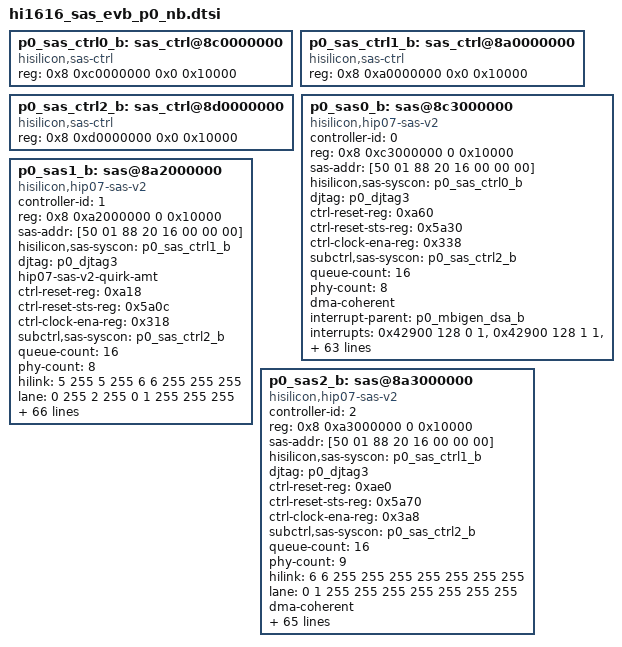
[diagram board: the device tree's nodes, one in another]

		p0_sas_ctrl0_b: sas_ctrl@8c0000000 {
			compatible = "hisilicon,sas-ctrl", "syscon";
			reg = <0x8 0xc0000000 0x0 0x10000>;
		};

		p0_sas_ctrl1_b: sas_ctrl@8a0000000 {
			compatible = "hisilicon,sas-ctrl", "syscon";
			reg = <0x8 0xa0000000 0x0 0x10000>;
		};

		p0_sas_ctrl2_b: sas_ctrl@8d0000000 {
			compatible = "hisilicon,sas-ctrl", "syscon";
			reg = <0x8 0xd0000000 0x0 0x10000>;
		};

		p0_sas0_b: sas@8c3000000 {
			compatible = "hisilicon,hip07-sas-v2";
			controller-id = <0>;
			reg = <0x8 0xc3000000 0 0x10000>;
			sas-addr = [50 01 88 20 16 00 00 00];
			hisilicon,sas-syscon = <&p0_sas_ctrl0_b>;
			djtag = <&p0_djtag3>;
			ctrl-reset-reg = <0xa60>;
			ctrl-reset-sts-reg = <0x5a30>;
			ctrl-clock-ena-reg = <0x338>;
			subctrl,sas-syscon = <&p0_sas_ctrl2_b>;
			queue-count = <16>;
			phy-count = <8>;
			dma-coherent;
			interrupt-parent = <&p0_mbigen_dsa_b>;
			interrupts = <0x42900 128 0 1>,
			<0x42900 128 1 1>,
			<0x42900 128 2 1>,
			<0x42900 128 3 1>,
			<0x42900 128 4 1>,
			<0x42900 128 5 1>,
			<0x42900 128 6 1>,
			<0x42900 128 7 1>,
			<0x42900 128 8 1>,
			<0x42900 128 9 1>,
			<0x42900 128 10 1>,
			<0x42900 128 11 1>,
			<0x42900 128 12 1>,
			<0x42900 128 13 1>,
			<0x42900 128 14 1>,
			<0x42900 128 15 1>,
			<0x42900 128 16 1>,
			<0x42900 128 17 1>,
			<0x42900 128 18 1>,
			<0x42900 128 19 1>,
			<0x42900 128 20 1>,
			<0x42900 128 21 1>,
			<0x42900 128 22 1>,
			<0x42900 128 23 1>,
			<0x42900 128 24 1>,
			<0x42900 128 25 1>,
			<0x42900 128 26 1>,
			<0x42900 128 27 1>,
			<0x42900 128 28 1>,
			<0x42900 128 29 1>,
			<0x42900 128 30 1>,
			<0x42900 128 31 1>,
			<0x42900 128 32 1>,
			<0x42900 128 33 1>,
			<0x42900 128 34 1>,
			<0x42900 128 35 1>,
			<0x42900 128 36 1>,
			<0x42900 128 37 1>,
			<0x42900 128 38 1>,
			<0x42900 128 39 1>,
			<0x42900 128 40 1>,
			<0x42900 128 41 1>,
			<0x42900 128 42 1>,
			<0x42900 128 43 1>,
			<0x42900 128 44 1>,
			<0x42900 128 45 1>,
			<0x42900 128 46 1>,
			<0x42900 128 47 1>,
			<0x42900 128 48 1>,
			<0x42900 128 49 1>,
			<0x42900 128 50 1>,
			<0x42900 128 51 1>,
			<0x42900 128 52 1>,
			<0x42900 128 53 1>,
			<0x42900 128 54 1>,
			<0x42900 128 55 1>,
			<0x42900 128 56 1>,
			<0x42900 128 57 1>,
			<0x42900 128 58 1>,
			<0x42900 128 59 1>,
			<0x42900 128 60 1>,
			<0x42900 128 61 1>,
			<0x42900 128 62 1>,
			<0x42900 128 63 1>,
			<0x42900 128 64 1>,
			<0x42900 128 65 1>,
			<0x42900 128 66 1>,
			<0x42900 128 67 1>,
			<0x42900 128 68 1>,
			<0x42900 128 69 1>,
			<0x42900 128 70 1>,
			<0x42900 128 71 1>,
			<0x42900 128 72 1>,
			<0x42900 128 73 1>,
			<0x42900 128 74 1>,
			<0x42900 128 75 1>,
			<0x42900 128 76 1>,
			<0x42900 128 77 1>,
			<0x42900 128 78 1>,
			<0x42900 128 79 1>,
			<0x42900 128 80 1>,
			<0x42900 128 81 1>,
			<0x42900 128 82 1>,
			<0x42900 128 83 1>,
			<0x42900 128 84 1>,
			<0x42900 128 85 1>,
			<0x42900 128 86 1>,
			<0x42900 128 87 1>,
			<0x42900 128 88 1>,
			<0x42900 128 89 1>,
			<0x42900 128 90 1>,
			<0x42900 128 91 1>,
			<0x42900 128 92 1>,
			<0x42900 128 93 1>,
			<0x42900 128 94 1>,
			<0x42900 128 95 1>,
			<0x42900 128 25 5>,
			<0x42900 128 26 5>,
			<0x42900 128 27 5>,
			<0x42900 128 28 5>,
			<0x42900 128 29 5>,
			<0x42900 128 30 5>,
			<0x42900 128 31 5>,
			<0x42900 128 32 5>,
			<0x42900 128 33 5>,
			<0x42900 128 34 5>,
			<0x42900 128 35 5>,
			<0x42900 128 36 5>,
			<0x42900 128 37 5>,
			<0x42900 128 38 5>,
			<0x42900 128 39 5>,
			<0x42900 128 40 5>,
			<0x42900 128 41 5>,
			<0x42900 128 42 5>,
			<0x42900 128 43 5>,
			<0x42900 128 44 5>,
			<0x42900 128 45 5>,
			<0x42900 128 46 5>,
			<0x42900 128 47 5>,
			<0x42900 128 48 5>,
			<0x42900 128 49 5>,
			<0x42900 128 50 5>,
			<0x42900 128 51 5>,
			<0x42900 128 52 5>,
			<0x42900 128 53 5>,
			<0x42900 128 54 5>,
			<0x42900 128 55 5>,
			<0x42900 128 56 5>;
			status = "ok";
		};

		p0_sas1_b: sas@8a2000000 {
			compatible = "hisilicon,hip07-sas-v2";
			controller-id = <1>;
			reg = <0x8 0xa2000000 0 0x10000>;
			sas-addr = [50 01 88 20 16 00 00 00];
			hisilicon,sas-syscon = <&p0_sas_ctrl1_b>;
			djtag = <&p0_djtag3>;
			hip07-sas-v2-quirk-amt;
			ctrl-reset-reg = <0xa18>;
			ctrl-reset-sts-reg = <0x5a0c>;
			ctrl-clock-ena-reg = <0x318>;
			subctrl,sas-syscon = <&p0_sas_ctrl2_b>;
			queue-count = <16>;
			phy-count = <8>;
			hilink = <5 255 5 255 6 6 255 255 255>;
			lane = <0 255 2 255 0 1 255 255 255>;
			dma-coherent;
			interrupt-parent = <&p0_mbigen_pcie_b>;
			interrupts = <0x42000 128 0 1>,
			<0x42000 128 1 1>,
			<0x42000 128 2 1>,
			<0x42000 128 3 1>,
			<0x42000 128 4 1>,
			<0x42000 128 5 1>,
			<0x42000 128 6 1>,
			<0x42000 128 7 1>,
			<0x42000 128 8 1>,
			<0x42000 128 9 1>,
			<0x42000 128 10 1>,
			<0x42000 128 11 1>,
			<0x42000 128 12 1>,
			<0x42000 128 13 1>,
			<0x42000 128 14 1>,
			<0x42000 128 15 1>,
			<0x42000 128 16 1>,
			<0x42000 128 17 1>,
			<0x42000 128 18 1>,
			<0x42000 128 19 1>,
			<0x42000 128 20 1>,
			<0x42000 128 21 1>,
			<0x42000 128 22 1>,
			<0x42000 128 23 1>,
			<0x42000 128 24 1>,
			<0x42000 128 25 1>,
			<0x42000 128 26 1>,
			<0x42000 128 27 1>,
			<0x42000 128 28 1>,
			<0x42000 128 29 1>,
			<0x42000 128 30 1>,
			<0x42000 128 31 1>,
			<0x42000 128 32 1>,
			<0x42000 128 33 1>,
			<0x42000 128 34 1>,
			<0x42000 128 35 1>,
			<0x42000 128 36 1>,
			<0x42000 128 37 1>,
			<0x42000 128 38 1>,
			<0x42000 128 39 1>,
			<0x42000 128 40 1>,
			<0x42000 128 41 1>,
			<0x42000 128 42 1>,
			<0x42000 128 43 1>,
			<0x42000 128 44 1>,
			<0x42000 128 45 1>,
			<0x42000 128 46 1>,
			<0x42000 128 47 1>,
			<0x42000 128 48 1>,
			<0x42000 128 49 1>,
			<0x42000 128 50 1>,
			<0x42000 128 51 1>,
			<0x42000 128 52 1>,
			<0x42000 128 53 1>,
			<0x42000 128 54 1>,
			<0x42000 128 55 1>,
			<0x42000 128 56 1>,
			<0x42000 128 57 1>,
			<0x42000 128 58 1>,
			<0x42000 128 59 1>,
			<0x42000 128 60 1>,
			<0x42000 128 61 1>,
			<0x42000 128 62 1>,
			<0x42000 128 63 1>,
			<0x42000 128 64 1>,
			<0x42000 128 65 1>,
			<0x42000 128 66 1>,
			<0x42000 128 67 1>,
			<0x42000 128 68 1>,
			<0x42000 128 69 1>,
			<0x42000 128 70 1>,
			<0x42000 128 71 1>,
			<0x42000 128 72 1>,
			<0x42000 128 73 1>,
			<0x42000 128 74 1>,
			<0x42000 128 75 1>,
			<0x42000 128 76 1>,
			<0x42000 128 77 1>,
			<0x42000 128 78 1>,
			<0x42000 128 79 1>,
			<0x42000 128 80 1>,
			<0x42000 128 81 1>,
			<0x42000 128 82 1>,
			<0x42000 128 83 1>,
			<0x42000 128 84 1>,
			<0x42000 128 85 1>,
			<0x42000 128 86 1>,
			<0x42000 128 87 1>,
			<0x42000 128 88 1>,
			<0x42000 128 89 1>,
			<0x42000 128 90 1>,
			<0x42000 128 91 1>,
			<0x42000 128 92 1>,
			<0x42000 128 93 1>,
			<0x42000 128 94 1>,
			<0x42000 128 95 1>,
			<0x42000 128 0 5>,
			<0x42000 128 1 5>,
			<0x42000 128 2 5>,
			<0x42000 128 3 5>,
			<0x42000 128 4 5>,
			<0x42000 128 5 5>,
			<0x42000 128 6 5>,
			<0x42000 128 7 5>,
			<0x42000 128 8 5>,
			<0x42000 128 9 5>,
			<0x42000 128 10 5>,
			<0x42000 128 11 5>,
			<0x42000 128 12 5>,
			<0x42000 128 13 5>,
			<0x42000 128 14 5>,
			<0x42000 128 15 5>,
			<0x42000 128 16 5>,
			<0x42000 128 17 5>,
			<0x42000 128 18 5>,
			<0x42000 128 19 5>,
			<0x42000 128 20 5>,
			<0x42000 128 21 5>,
			<0x42000 128 22 5>,
			<0x42000 128 23 5>,
			<0x42000 128 24 5>,
			<0x42000 128 25 5>,
			<0x42000 128 26 5>,
			<0x42000 128 27 5>,
			<0x42000 128 28 5>,
			<0x42000 128 29 5>,
			<0x42000 128 31 5>,
			<0x42000 128 31 5>;
			status = "ok";
		};

		p0_sas2_b: sas@8a3000000 {
			compatible = "hisilicon,hip07-sas-v2";
			controller-id = <2>;
			reg = <0x8 0xa3000000 0 0x10000>;
			sas-addr = [50 01 88 20 16 00 00 00];
			hisilicon,sas-syscon = <&p0_sas_ctrl1_b>;
			djtag = <&p0_djtag3>;
			ctrl-reset-reg = <0xae0>;
			ctrl-reset-sts-reg = <0x5a70>;
			ctrl-clock-ena-reg = <0x3a8>;
			subctrl,sas-syscon = <&p0_sas_ctrl2_b>;
			queue-count = <16>;
			phy-count = <9>;
			hilink = <6 6 255 255 255 255 255 255 255>;
			lane = <0 1 255 255 255 255 255 255 255>;
			dma-coherent;
			interrupt-parent = <&p0_mbigen_pcie_b>;
			interrupts = <0x42040 128 0 2>,
			<0x42040 128 1 2>,
			<0x42040 128 2 2>,
			<0x42040 128 3 2>,
			<0x42040 128 4 2>,
			<0x42040 128 5 2>,
			<0x42040 128 6 2>,
			<0x42040 128 7 2>,
			<0x42040 128 8 2>,
			<0x42040 128 9 2>,
			<0x42040 128 10 2>,
			<0x42040 128 11 2>,
			<0x42040 128 12 2>,
			<0x42040 128 13 2>,
			<0x42040 128 14 2>,
			<0x42040 128 15 2>,
			<0x42040 128 16 2>,
			<0x42040 128 17 2>,
			<0x42040 128 18 2>,
			<0x42040 128 19 2>,
			<0x42040 128 20 2>,
			<0x42040 128 21 2>,
			<0x42040 128 22 2>,
			<0x42040 128 23 2>,
			<0x42040 128 24 2>,
			<0x42040 128 25 2>,
			<0x42040 128 26 2>,
			<0x42040 128 27 2>,
			<0x42040 128 28 2>,
			<0x42040 128 29 2>,
			<0x42040 128 30 2>,
			<0x42040 128 31 2>,
			<0x42040 128 32 2>,
			<0x42040 128 33 2>,
			<0x42040 128 34 2>,
			<0x42040 128 35 2>,
			<0x42040 128 36 2>,
			<0x42040 128 37 2>,
			<0x42040 128 38 2>,
			<0x42040 128 39 2>,
			<0x42040 128 40 2>,
			<0x42040 128 41 2>,
			<0x42040 128 42 2>,
			<0x42040 128 43 2>,
			<0x42040 128 44 2>,
			<0x42040 128 45 2>,
			<0x42040 128 46 2>,
			<0x42040 128 47 2>,
			<0x42040 128 48 2>,
			<0x42040 128 49 2>,
			<0x42040 128 50 2>,
			<0x42040 128 51 2>,
			<0x42040 128 52 2>,
			<0x42040 128 53 2>,
			<0x42040 128 54 2>,
			<0x42040 128 55 2>,
			<0x42040 128 56 2>,
			<0x42040 128 57 2>,
			<0x42040 128 58 2>,
			<0x42040 128 59 2>,
			<0x42040 128 60 2>,
			<0x42040 128 61 2>,
			<0x42040 128 62 2>,
			<0x42040 128 63 2>,
			<0x42040 128 64 2>,
			<0x42040 128 65 2>,
			<0x42040 128 66 2>,
			<0x42040 128 67 2>,
			<0x42040 128 68 2>,
			<0x42040 128 69 2>,
			<0x42040 128 70 2>,
			<0x42040 128 71 2>,
			<0x42040 128 72 2>,
			<0x42040 128 73 2>,
			<0x42040 128 74 2>,
			<0x42040 128 75 2>,
			<0x42040 128 76 2>,
			<0x42040 128 77 2>,
			<0x42040 128 78 2>,
			<0x42040 128 79 2>,
			<0x42040 128 80 2>,
			<0x42040 128 81 2>,
			<0x42040 128 82 2>,
			<0x42040 128 83 2>,
			<0x42040 128 84 2>,
			<0x42040 128 85 2>,
			<0x42040 128 86 2>,
			<0x42040 128 87 2>,
			<0x42040 128 88 2>,
			<0x42040 128 89 2>,
			<0x42040 128 90 2>,
			<0x42040 128 91 2>,
			<0x42040 128 92 2>,
			<0x42040 128 93 2>,
			<0x42040 128 94 2>,
			<0x42040 128 95 2>,
			<0x42040 128 32 5>,
			<0x42040 128 33 5>,
			<0x42040 128 34 5>,
			<0x42040 128 35 5>,
			<0x42040 128 36 5>,
			<0x42040 128 37 5>,
			<0x42040 128 38 5>,
			<0x42040 128 39 5>,
			<0x42040 128 40 5>,
			<0x42040 128 41 5>,
			<0x42040 128 42 5>,
			<0x42040 128 43 5>,
			<0x42040 128 44 5>,
			<0x42040 128 45 5>,
			<0x42040 128 46 5>,
			<0x42040 128 47 5>,
			<0x42040 128 48 5>,
			<0x42040 128 49 5>,
			<0x42040 128 50 5>,
			<0x42040 128 51 5>,
			<0x42040 128 52 5>,
			<0x42040 128 53 5>,
			<0x42040 128 54 5>,
			<0x42040 128 55 5>,
			<0x42040 128 56 5>,
			<0x42040 128 57 5>,
			<0x42040 128 58 5>,
			<0x42040 128 59 5>,
			<0x42040 128 60 5>,
			<0x42040 128 61 5>,
			<0x42040 128 62 5>,
			<0x42040 128 63 5>;
			status = "ok";
		};
